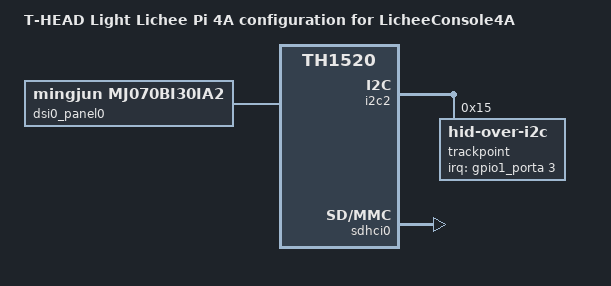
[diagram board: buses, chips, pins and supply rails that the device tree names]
/* SPDX-License-Identifier: GPL-2.0 */
/*
 * Copyright (C) 2023 Sipeed.
 */

#include <dt-bindings/interrupt-controller/irq.h>
#include "th1520-lpi4a-laptop.dts"

/ {
        model = "T-HEAD Light Lichee Pi 4A configuration for LicheeConsole4A";
};

&dsi0_panel0 {
	compatible = "mingjun,mj070bi30ia2";
};

&i2c2 {
	/* thank ice */
	trackpoint: trackpad@15 {
		compatible = "hid-over-i2c";
		reg = <0x15>;
		hid-descr-addr = <0x0020>;
		interrupt-parent = <&gpio1_porta>;
		interrupts = <3 IRQ_TYPE_LEVEL_LOW>;
	};
};

&cw2015 {
	cellwise,battery-profile = /bits/ 8 <
		0x17 0x67 0x72 0x68 0x66 0x63 0x62 0x5A
		0x64 0x61 0x4D 0x57 0x5A 0x51 0x43 0x38
		0x31 0x2A 0x24 0x22 0x29 0x31 0x3E 0x4C
		0x29 0x4D 0x0B 0x85 0x1C 0x38 0x47 0x57
		0x5D 0x5E 0x5F 0x60 0x3F 0x1A 0x6F 0x41
		0x0A 0x43 0x12 0x38 0x7B 0x95 0x9A 0x18
		0x4B 0x6F 0x9E 0xD5 0x80 0x57 0x87 0xCB
		0x2F 0x00 0x64 0xA5 0xB5 0x13 0x54 0xB9
	>;
};

&lcd0_backlight {
        default-brightness-level = <50>;
};

&sdhci0 {
        max-frequency = <35000000>;
        status = "okay";
};

&fan {
        cooling-levels = <255 255 255 255>;
};
